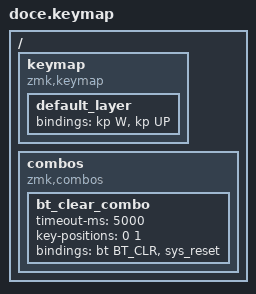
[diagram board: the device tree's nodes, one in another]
#include <behaviors.dtsi>
#include <dt-bindings/zmk/keys.h>
#include <dt-bindings/zmk/bt.h>

/{
    keymap {
        compatible = "zmk,keymap";

        default_layer {
              bindings = <
                  &kp W    &kp UP
              >;
        };
    };

    combos {
        compatible = "zmk,combos";

        bt_clear_combo {
            timeout-ms =<5000>;
            key-positions = <0 1>;
            bindings =<&bt BT_CLR &sys_reset>;
        };
    };
};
